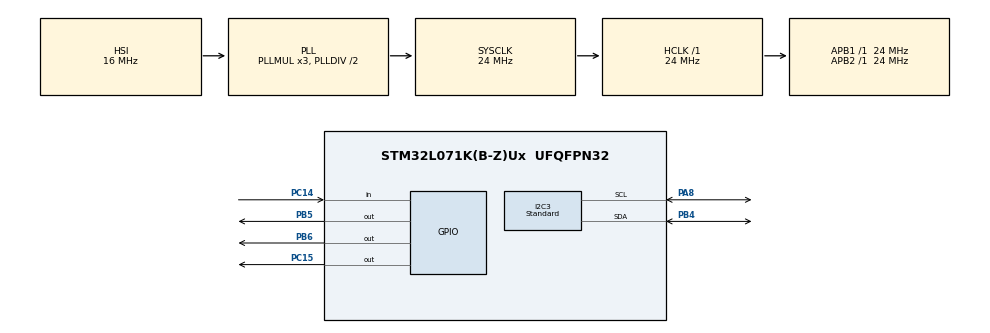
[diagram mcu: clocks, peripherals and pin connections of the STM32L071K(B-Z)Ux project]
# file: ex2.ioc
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I2C3.AddressingMode=I2C_ADDRESSINGMODE_7BIT
I2C3.Analog_Filter=I2C_ANALOGFILTER_ENABLE
I2C3.GeneralCallMode=I2C_GENERALCALL_DISABLE
I2C3.I2C_Fall_Time=250
I2C3.I2C_Rise_Time=250
I2C3.I2C_Speed_Mode=I2C_Standard
I2C3.NoStretchMode=I2C_NOSTRETCH_DISABLE
I2C3.Timing=0x00B25C80
Mcu.Family=STM32L0
Mcu.Name=STM32L071K(B-Z)Ux
Mcu.Package=UFQFPN32
PA8.GPIO_PuPdOD=GPIO_PULLUP
PA8.Mode=I2C
PA8.Signal=I2C3_SCL
PB4.GPIO_PuPdOD=GPIO_PULLUP
PB4.Mode=I2C
PB4.Signal=I2C3_SDA
PB5.Signal=GPIO_Output
PB6.Signal=GPIO_Output
PC14-OSC32_IN.Signal=GPIO_Input
PC15-OSC32_OUT.Signal=GPIO_Output
ProjectManager.HeapSize=0x200
ProjectManager.StackSize=0x400
ProjectManager.TargetToolchain=MDK-ARM V5
RCC.AHBFreq_Value=24000000
RCC.APB1Freq_Value=24000000
RCC.APB1TimFreq_Value=24000000
RCC.APB2Freq_Value=24000000
RCC.APB2TimFreq_Value=24000000
RCC.HCLKFreq_Value=24000000
RCC.HSI16_VALUE=16000000
RCC.HSI_VALUE=16000000
RCC.LSE_VALUE=32768
RCC.MSI_VALUE=2097000
RCC.SYSCLKFreq_VALUE=24000000
RCC.SYSCLKSource=RCC_SYSCLKSOURCE_PLLCLK
RCC.VCOOutputFreq_Value=48000000
board=custom

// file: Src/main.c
/* USER CODE BEGIN Header */
/**
  ******************************************************************************
  * @file           : main.c
  * @brief          : Main program body
  ******************************************************************************
  * @attention
  *
  * <h2><center>&copy; Copyright (c) 2019 STMicroelectronics.
  * All rights reserved.</center></h2>
  *
  * This software component is licensed by ST under BSD 3-Clause license,
  * the "License"; You may not use this file except in compliance with the
  * License. You may obtain a copy of the License at:
  *                        opensource.org/licenses/BSD-3-Clause
  *
  ******************************************************************************
  */
/* USER CODE END Header */

#include "main.h"

/* USER CODE BEGIN Includes */
#include "main_task.h"
/* USER CODE END Includes */

I2C_HandleTypeDef hi2c3;

void SystemClock_Config(void);
static void MX_GPIO_Init(void);
static void MX_I2C3_Init(void);

int main(void)
{

    /* MCU Configuration--------------------------------------------------------*/

    /* Reset of all peripherals, Initializes the Flash interface and the Systick. */
    HAL_Init();

    /* Configure the system clock */
    SystemClock_Config();

    /* Initialize all configured peripherals */
    MX_GPIO_Init();
    MX_I2C3_Init();
    /* USER CODE BEGIN 2 */
    Task_BrdInit();
    /* USER CODE END 2 */

    /* Infinite loop */
    /* USER CODE BEGIN WHILE */
    while (1)
    {
        Task_Main();
        /* USER CODE END WHILE */

    }
}

void SystemClock_Config(void)
{
    RCC_OscInitTypeDef RCC_OscInitStruct = {0};
    RCC_ClkInitTypeDef RCC_ClkInitStruct = {0};
    RCC_PeriphCLKInitTypeDef PeriphClkInit = {0};

    /** Configure the main internal regulator output voltage
    */
    __HAL_PWR_VOLTAGESCALING_CONFIG(PWR_REGULATOR_VOLTAGE_SCALE1);
    /** Initializes the CPU, AHB and APB busses clocks
    */
    RCC_OscInitStruct.OscillatorType = RCC_OSCILLATORTYPE_HSI;
    RCC_OscInitStruct.HSIState = RCC_HSI_ON;
    RCC_OscInitStruct.HSICalibrationValue = RCC_HSICALIBRATION_DEFAULT;
    RCC_OscInitStruct.PLL.PLLState = RCC_PLL_ON;
    RCC_OscInitStruct.PLL.PLLSource = RCC_PLLSOURCE_HSI;
    RCC_OscInitStruct.PLL.PLLMUL = RCC_PLLMUL_3;
    RCC_OscInitStruct.PLL.PLLDIV = RCC_PLLDIV_2;
    if (HAL_RCC_OscConfig(&RCC_OscInitStruct) != HAL_OK)
    {
        Error_Handler();
    }
    /** Initializes the CPU, AHB and APB busses clocks
    */
    RCC_ClkInitStruct.ClockType = RCC_CLOCKTYPE_HCLK | RCC_CLOCKTYPE_SYSCLK
                                  | RCC_CLOCKTYPE_PCLK1 | RCC_CLOCKTYPE_PCLK2;
    RCC_ClkInitStruct.SYSCLKSource = RCC_SYSCLKSOURCE_PLLCLK;
    RCC_ClkInitStruct.AHBCLKDivider = RCC_SYSCLK_DIV1;
    RCC_ClkInitStruct.APB1CLKDivider = RCC_HCLK_DIV1;
    RCC_ClkInitStruct.APB2CLKDivider = RCC_HCLK_DIV1;

    if (HAL_RCC_ClockConfig(&RCC_ClkInitStruct, FLASH_LATENCY_1) != HAL_OK)
    {
        Error_Handler();
    }
    PeriphClkInit.PeriphClockSelection = RCC_PERIPHCLK_I2C3;
    PeriphClkInit.I2c3ClockSelection = RCC_I2C3CLKSOURCE_PCLK1;
    if (HAL_RCCEx_PeriphCLKConfig(&PeriphClkInit) != HAL_OK)
    {
        Error_Handler();
    }
}

static void MX_I2C3_Init(void)
{

    hi2c3.Instance = I2C3;
    hi2c3.Init.Timing = 0x00B25C80;
    hi2c3.Init.OwnAddress1 = 0;
    hi2c3.Init.AddressingMode = I2C_ADDRESSINGMODE_7BIT;
    hi2c3.Init.DualAddressMode = I2C_DUALADDRESS_DISABLE;
    hi2c3.Init.OwnAddress2 = 0;
    hi2c3.Init.OwnAddress2Masks = I2C_OA2_NOMASK;
    hi2c3.Init.GeneralCallMode = I2C_GENERALCALL_DISABLE;
    hi2c3.Init.NoStretchMode = I2C_NOSTRETCH_DISABLE;
    if (HAL_I2C_Init(&hi2c3) != HAL_OK)
    {
        Error_Handler();
    }
    /** Configure Analogue filter
    */
    if (HAL_I2CEx_ConfigAnalogFilter(&hi2c3, I2C_ANALOGFILTER_ENABLE) != HAL_OK)
    {
        Error_Handler();
    }
    /** Configure Digital filter
    */
    if (HAL_I2CEx_ConfigDigitalFilter(&hi2c3, 0) != HAL_OK)
    {
        Error_Handler();
    }

}

static void MX_GPIO_Init(void)
{
    GPIO_InitTypeDef GPIO_InitStruct = {0};

    /* GPIO Ports Clock Enable */
    __HAL_RCC_GPIOC_CLK_ENABLE();
    __HAL_RCC_GPIOA_CLK_ENABLE();
    __HAL_RCC_GPIOB_CLK_ENABLE();

    /*Configure GPIO pin Output Level */
    HAL_GPIO_WritePin(GPIOC, GPIO_PIN_15, GPIO_PIN_RESET);

    /*Configure GPIO pin Output Level */
    HAL_GPIO_WritePin(GPIOB, GPIO_PIN_5 | GPIO_PIN_6, GPIO_PIN_RESET);

    /*Configure GPIO pin : PC14 */
    GPIO_InitStruct.Pin = GPIO_PIN_14;
    GPIO_InitStruct.Mode = GPIO_MODE_INPUT;
    GPIO_InitStruct.Pull = GPIO_NOPULL;
    HAL_GPIO_Init(GPIOC, &GPIO_InitStruct);

    /*Configure GPIO pin : PC15 */
    GPIO_InitStruct.Pin = GPIO_PIN_15;
    GPIO_InitStruct.Mode = GPIO_MODE_OUTPUT_PP;
    GPIO_InitStruct.Pull = GPIO_NOPULL;
    GPIO_InitStruct.Speed = GPIO_SPEED_FREQ_LOW;
    HAL_GPIO_Init(GPIOC, &GPIO_InitStruct);

    /*Configure GPIO pins : PB5 PB6 */
    GPIO_InitStruct.Pin = GPIO_PIN_5 | GPIO_PIN_6;
    GPIO_InitStruct.Mode = GPIO_MODE_OUTPUT_PP;
    GPIO_InitStruct.Pull = GPIO_NOPULL;
    GPIO_InitStruct.Speed = GPIO_SPEED_FREQ_LOW;
    HAL_GPIO_Init(GPIOB, &GPIO_InitStruct);

}

void Error_Handler(void)
{
}

/************************ (C) COPYRIGHT STMicroelectronics *****END OF FILE****/
